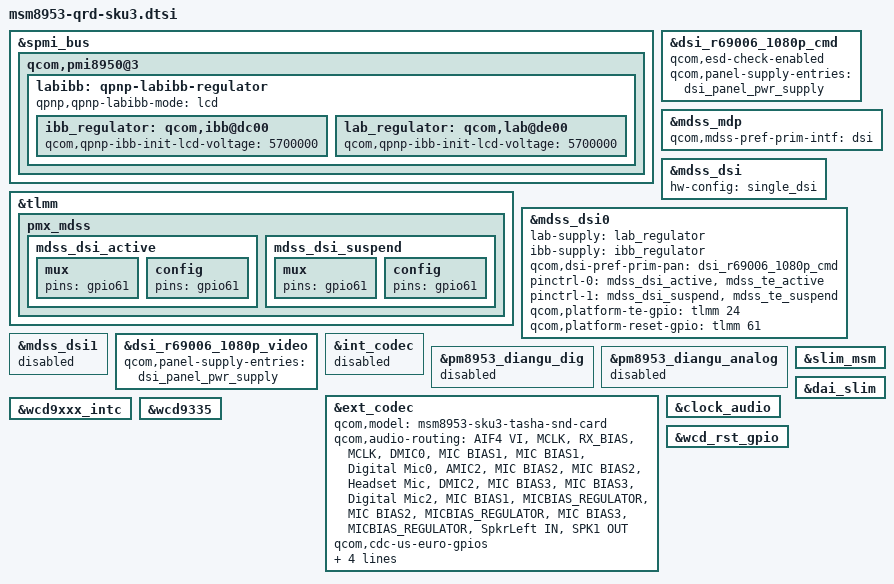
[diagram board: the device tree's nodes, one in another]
/*
 * Copyright (c) 2015-2016, The Linux Foundation. All rights reserved.
 *
 * This program is free software; you can redistribute it and/or modify
 * it under the terms of the GNU General Public License version 2 and
 * only version 2 as published by the Free Software Foundation.
 *
 * This program is distributed in the hope that it will be useful,
 * but WITHOUT ANY WARRANTY; without even the implied warranty of
 * MERCHANTABILITY or FITNESS FOR A PARTICULAR PURPOSE.  See the
 * GNU General Public License for more details.
 */

#include "msm8953-qrd.dtsi"

&spmi_bus {
	qcom,pmi8950@3 {
		labibb: qpnp-labibb-regulator {
			ibb_regulator: qcom,ibb@dc00 {
				/delete-property/
					qcom,qpnp-ibb-use-default-voltage;
				qcom,qpnp-ibb-init-lcd-voltage = <5700000>;
			};

			lab_regulator: qcom,lab@de00 {
				/delete-property/
					qcom,qpnp-ibb-use-default-voltage;
				qcom,qpnp-ibb-init-lcd-voltage = <5700000>;
			};
		};
	};
};

#include "msm8953-mdss-panels.dtsi"

&tlmm {
	pmx_mdss {
		mdss_dsi_active: mdss_dsi_active {
			mux {
				pins = "gpio61";
			};
			config {
				pins = "gpio61";
			};
		};
		mdss_dsi_suspend: mdss_dsi_suspend {
			mux {
				pins = "gpio61";
			};
			config {
				pins = "gpio61";
			};
		};
	};
};

&dsi_r69006_1080p_cmd {
	qcom,esd-check-enabled;
};

&mdss_mdp {
	qcom,mdss-pref-prim-intf = "dsi";
};

&mdss_dsi {
	hw-config = "single_dsi";
};

&mdss_dsi0 {
	lab-supply = <&lab_regulator>;
	ibb-supply = <&ibb_regulator>;
	/delete-property/ vdd-supply;

	qcom,dsi-pref-prim-pan = <&dsi_r69006_1080p_cmd>;
	pinctrl-names = "mdss_default", "mdss_sleep";
	pinctrl-0 = <&mdss_dsi_active &mdss_te_active>;
	pinctrl-1 = <&mdss_dsi_suspend &mdss_te_suspend>;
	qcom,platform-te-gpio = <&tlmm 24 0>;
	qcom,platform-reset-gpio = <&tlmm 61 0>;
};

&mdss_dsi1 {
	status = "disabled";
};

&labibb {
	status = "ok";
	qpnp,qpnp-labibb-mode = "lcd";
};

&dsi_r69006_1080p_cmd {
	qcom,panel-supply-entries = <&dsi_panel_pwr_supply>;
};

&dsi_r69006_1080p_video {
	qcom,panel-supply-entries = <&dsi_panel_pwr_supply>;
};

&int_codec {
	status = "disabled";
};

&pm8953_diangu_dig {
	status = "disabled";
};

&pm8953_diangu_analog {
	status = "disabled";
};

&ext_codec {
	status = "ok";
	qcom,model = "msm8953-sku3-tasha-snd-card";

	qcom,audio-routing =
		"AIF4 VI", "MCLK",
		"RX_BIAS", "MCLK",
		"DMIC0", "MIC BIAS1",
		"MIC BIAS1", "Digital Mic0",
		"AMIC2", "MIC BIAS2",
		"MIC BIAS2", "Headset Mic",
		"DMIC2", "MIC BIAS3",
		"MIC BIAS3", "Digital Mic2",
		"MIC BIAS1", "MICBIAS_REGULATOR",
		"MIC BIAS2", "MICBIAS_REGULATOR",
		"MIC BIAS3", "MICBIAS_REGULATOR",
		"SpkrLeft IN", "SPK1 OUT";

	qcom,cdc-us-euro-gpios;

	qcom,msm-mbhc-hphl-swh = <1>;

	qcom,wsa-max-devs = <1>;
	qcom,wsa-devs = <&wsa881x_211>, <&wsa881x_213>;
	qcom,wsa-aux-dev-prefix = "SpkrLeft", "SpkrLeft";
};

&slim_msm {
	status = "ok";
};

&dai_slim {
	status = "ok";
};

&wcd9xxx_intc {
	status = "ok";
};

&clock_audio {
	status = "ok";
};

&wcd9335 {
	status = "ok";
};

&wcd_rst_gpio {
	status = "ok";
};
